# ESP32-C6 register map
Vendor: ESPRESSIF SYSTEMS (SHANGHAI) CO., LTD.; Series: ESP32 C-Series; File version: 12
CPU: RV32IMAC r0p0, little endian, no MPU, no FPU, 0 interrupt priority bits
Address unit: 32 bits
Registers are 32-bit, read-write, reset 0x0 unless marked. A register's access mark holds for its fields unless they carry their own. Offsets are from the block's base; [hi:lo] are bit positions; {n}, {i} and the like mark numbered series.

## HINF — HINF Peripheral
Base 0x60016000
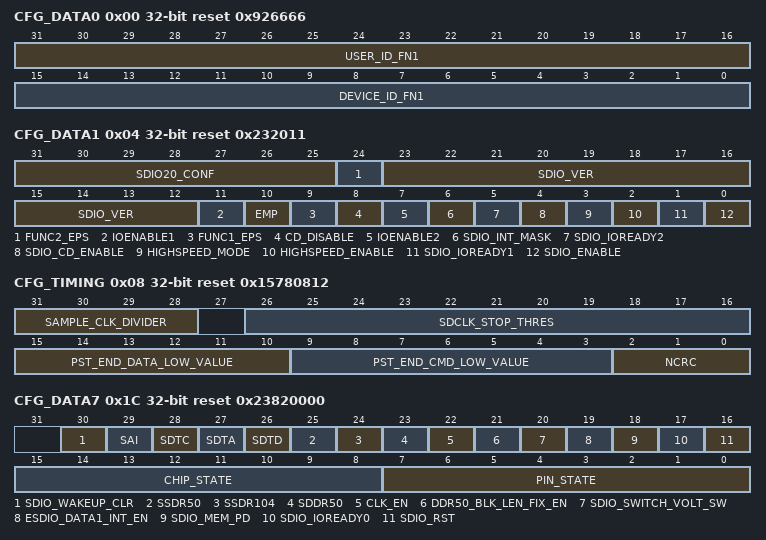
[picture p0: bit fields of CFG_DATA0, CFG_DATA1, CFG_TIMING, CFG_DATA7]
0x00 CFG_DATA0 reset 0x926666 — Configure sdio cis content
  [31:16] USER_ID_FN1 — configure user id of function1 in cis
  [15:0] DEVICE_ID_FN1 — configure device id of function1 in cis
0x04 CFG_DATA1 access per field reset 0x232011 — SDIO configuration register
  [31:25] SDIO20_CONF rw — [29],sdio negedge sample enablel.[30],sdio posedge sample enable.[31],sdio cmd/dat in delayed cycles control,0:no delay, 1:delay 1 cycle. [25]: sdio1.1 dat/cmd sending out edge control,1:negedge,0:posedge when highseed mode. [26]: sdio2.0 dat/cmd sending out edge control,1:negedge when [12]=0,0:negedge when [12]=0,posedge when highspeed mode enable. [27]: sdio interrupt sending out delay control,1:delay one cycle, 0: no delay. [28]: sdio data pad pull up enable
  [24] FUNC2_EPS ro — function2 eps status in fbr
  [23:12] SDIO_VER rw — sdio version in cccr
  [11] IOENABLE1 ro — ioe1 status in cccr
  [10] EMP ro — empc status in cccr
  [9] FUNC1_EPS ro — function1 eps status in fbr
  [8] CD_DISABLE ro — card disable status in cccr
  [7] IOENABLE2 ro — ioe2 status in cccr
  [6] SDIO_INT_MASK rw — mask sdio interrupt in cccr, high active
  [5] SDIO_IOREADY2 rw — sdio function1 io ready signal in cis
  [4] SDIO_CD_ENABLE rw — sdio card detect enable
  [3] HIGHSPEED_MODE ro — highspeed mode status in cccr
  [2] HIGHSPEED_ENABLE rw — Highspeed enable in cccr
  [1] SDIO_IOREADY1 rw — sdio function1 io ready signal in cis
  [0] SDIO_ENABLE rw — Sdio clock enable
0x08 CFG_TIMING reset 0x15780812 — Timing configuration registers
  [31:28] SAMPLE_CLK_DIVIDER — module clk divider to sample sdclk
  [26:16] SDCLK_STOP_THRES — Configure the number of cycles of module clk to judge sdclk has stopped
  [15:10] PST_END_DATA_LOW_VALUE — configure cycles to lower data after voltage is changed to 1.8V.
  [9:3] PST_END_CMD_LOW_VALUE — configure cycles to lower cmd after voltage is changed to 1.8V.
  [2:0] NCRC — configure Ncrc parameter in sdr50/104 mode, no more than 6.
0x0C CFG_UPDATE wo — update sdio configurations
  [0] CONF_UPDATE — update the timing configurations
0x1C CFG_DATA7 access per field reset 0x23820000 — SDIO configuration register
  [30] SDIO_WAKEUP_CLR wo — clear sdio_wake_up signal after the chip wakes up
  [29] SAI rw — configure if support asynchronous interrupt in cccr
  [28] SDTC rw — configure if support driver type C in cccr
  [27] SDTA rw — configure if support driver type A in cccr
  [26] SDTD rw — configure if support driver type D in cccr
  [25] SSDR50 rw — configure if support ddr50 mode in cccr
  [24] SSDR104 rw — configure if support sdr104 mode in cccr
  [23] SDDR50 rw — configure if support sdr50 mode in cccr
  [22] CLK_EN rw — sdio apb clock for configuration force on control:0-gating,1-force on.
  [21] DDR50_BLK_LEN_FIX_EN rw — enable block length to be fixed to 512 bytes in ddr50 mode
  [20] SDIO_SWITCH_VOLT_SW rw — control switch voltage change to 1.8V by software. 0:3.3V,1:1.8V
  [19] ESDIO_DATA1_INT_EN rw — enable sdio interrupt on data1 line
  [18] SDIO_MEM_PD rw — sdio memory power down, high active
  [17] SDIO_IOREADY0 rw — sdio io ready, high enable
  [16] SDIO_RST rw — soft reset control for sdio module
  [15:8] CHIP_STATE rw — configure cis addr 312, 315, 568 and 571
  [7:0] PIN_STATE rw — configure cis addr 318 and 574
{0x20+4i} CIS_CONF_W{i} reset 0xFFFFFFFF (i=0..7) — SDIO cis configuration register
  [31:0] CIS_CONF_W{i} — Configure cis addr {4i+39}~{4i+36}
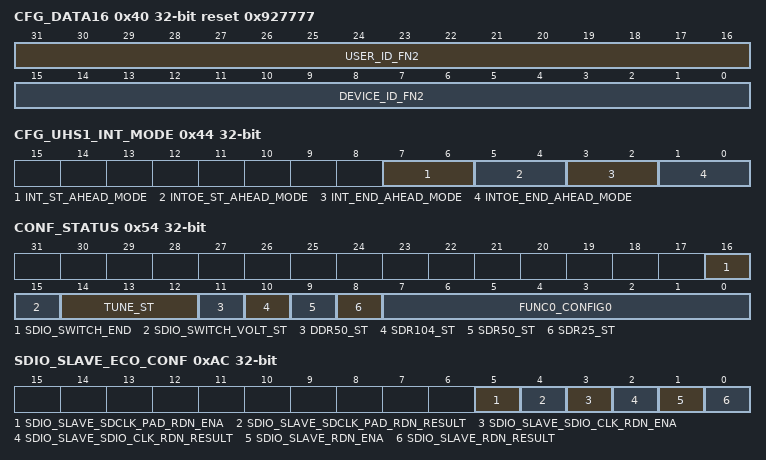
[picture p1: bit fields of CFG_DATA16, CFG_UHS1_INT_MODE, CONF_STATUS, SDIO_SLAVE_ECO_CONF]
0x40 CFG_DATA16 reset 0x927777 — SDIO cis configuration register
  [31:16] USER_ID_FN2 — configure user id of function2 in cis
  [15:0] DEVICE_ID_FN2 — configure device id of function2 in cis
0x44 CFG_UHS1_INT_MODE — configure int to start and end ahead of time in uhs1 mode
  [7:6] INT_ST_AHEAD_MODE — int on dat1 start ahead of time: 0/3-no, 1-ahead 1sdclk, 2-ahead 2sdclk
  [5:4] INTOE_ST_AHEAD_MODE — intoe on dat1 start ahead of time: 0/3-no, 1-ahead 1sdclk, 2-ahead 2sdclk
  [3:2] INT_END_AHEAD_MODE — int on dat1 end ahead of time: 0/3-no, 1-ahead 1sdclk, 2-ahead 2sdclk
  [1:0] INTOE_END_AHEAD_MODE — intoe on dat1 end ahead of time: 0/3-no, 1-ahead 1sdclk, 2-ahead 2sdclk
0x54 CONF_STATUS ro — func0 config0 status
  [16] SDIO_SWITCH_END — sdio switch voltage ldo ready
  [15] SDIO_SWITCH_VOLT_ST — sdio switch voltage status:0-3.3V, 1-1.8V.
  [14:12] TUNE_ST — tune_st fsm status
  [11] DDR50_ST — ddr50 status
  [10] SDR104_ST — sdr104 status
  [9] SDR50_ST — sdr50 status
  [8] SDR25_ST — sdr25 status
  [7:0] FUNC0_CONFIG0 — func0 config0 (addr: 0x20f0 ) status
0xA4 SDIO_SLAVE_ECO_LOW — sdio_slave redundant control registers
  [31:0] RDN_ECO_LOW — redundant registers for sdio_slave
0xA8 SDIO_SLAVE_ECO_HIGH reset 0xFFFFFFFF — sdio_slave redundant control registers
  [31:0] RDN_ECO_HIGH — redundant registers for sdio_slave
0xAC SDIO_SLAVE_ECO_CONF access per field — sdio_slave redundant control registers
  [5] SDIO_SLAVE_SDCLK_PAD_RDN_ENA rw — redundant registers for sdio_slave
  [4] SDIO_SLAVE_SDCLK_PAD_RDN_RESULT ro — redundant registers for sdio_slave
  [3] SDIO_SLAVE_SDIO_CLK_RDN_ENA rw — redundant registers for sdio_slave
  [2] SDIO_SLAVE_SDIO_CLK_RDN_RESULT ro — redundant registers for sdio_slave
  [1] SDIO_SLAVE_RDN_ENA rw — redundant registers for sdio_slave
  [0] SDIO_SLAVE_RDN_RESULT ro — redundant registers for sdio_slave
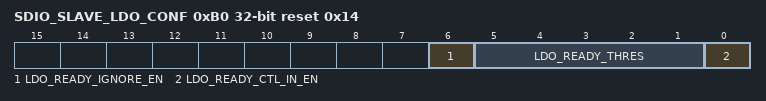
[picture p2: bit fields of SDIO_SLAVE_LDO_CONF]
0xB0 SDIO_SLAVE_LDO_CONF reset 0x14 — sdio slave ldo control register
  [6] LDO_READY_IGNORE_EN — ignore ldo ready signal
  [5:1] LDO_READY_THRES — configure ldo ready counting threshold value, the actual counting target is 2^(ldo_ready_thres)-1
  [0] LDO_READY_CTL_IN_EN — control ldo ready signal by sdio slave itself
0xFC SDIO_DATE reset 0x2203150 — ******* Description ***********
  [31:0] SDIO_DATE — sdio version date.
